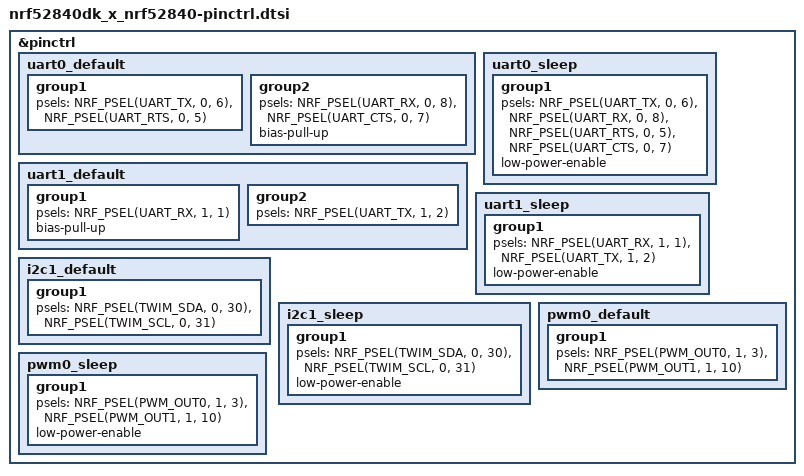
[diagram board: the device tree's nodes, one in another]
/*
 * Copyright (c) 2022 Nordic Semiconductor
 * SPDX-License-Identifier: Apache-2.0
 */

&pinctrl {
	uart0_default: uart0_default {
		group1 {
			psels = <NRF_PSEL(UART_TX, 0, 6)>,
				<NRF_PSEL(UART_RTS, 0, 5)>;
		};
		group2 {
			psels = <NRF_PSEL(UART_RX, 0, 8)>,
				<NRF_PSEL(UART_CTS, 0, 7)>;
			bias-pull-up;
		};
	};

	uart0_sleep: uart0_sleep {
		group1 {
			psels = <NRF_PSEL(UART_TX, 0, 6)>,
				<NRF_PSEL(UART_RX, 0, 8)>,
				<NRF_PSEL(UART_RTS, 0, 5)>,
				<NRF_PSEL(UART_CTS, 0, 7)>;
			low-power-enable;
		};
	};

	uart1_default: uart1_default {
		group1 {
			psels = <NRF_PSEL(UART_RX, 1, 1)>;
			bias-pull-up;
		};
		group2 {
			psels = <NRF_PSEL(UART_TX, 1, 2)>;
		};
	};

	uart1_sleep: uart1_sleep {
		group1 {
			psels = <NRF_PSEL(UART_RX, 1, 1)>,
				<NRF_PSEL(UART_TX, 1, 2)>;
			low-power-enable;
		};
	};

	i2c1_default: i2c1_default {
		group1 {
			psels = <NRF_PSEL(TWIM_SDA, 0, 30)>,
				<NRF_PSEL(TWIM_SCL, 0, 31)>;
		};
	};

	i2c1_sleep: i2c1_sleep {
		group1 {
			psels = <NRF_PSEL(TWIM_SDA, 0, 30)>,
				<NRF_PSEL(TWIM_SCL, 0, 31)>;
			low-power-enable;
		};
	};

	pwm0_default: pwm0_default {
		group1 {
			psels = <NRF_PSEL(PWM_OUT0, 1, 3)>,
				<NRF_PSEL(PWM_OUT1, 1, 10)>;
			/*nordic,invert;*/
		};
	};

	pwm0_sleep: pwm0_sleep {
		group1 {
			psels = <NRF_PSEL(PWM_OUT0, 1, 3)>,
				<NRF_PSEL(PWM_OUT1, 1, 10)>;
			low-power-enable;
		};
	};
};
